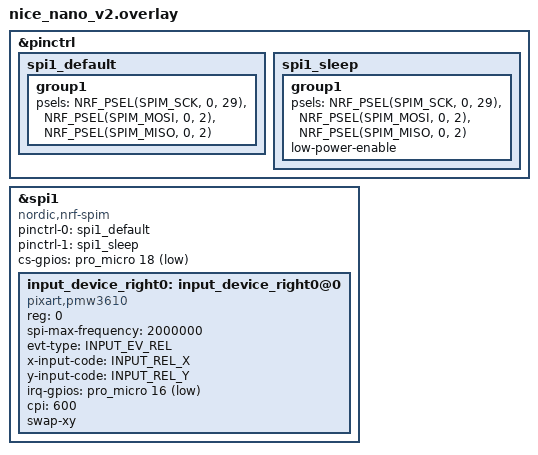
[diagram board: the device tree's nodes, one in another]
/**
 * Generated by Shield Wizard for ZMK
 * Applies to part "right" with controller "nice_nano_v2"
 */

// pin control for spi1
// - SCK on D20
// - MOSI on D19
// - MISO on D19
&pinctrl {
    /* configuration for spi1 device, default state */
    spi1_default: spi1_default {
        group1 {
            psels = <NRF_PSEL(SPIM_SCK, 0, 29)>,
                    <NRF_PSEL(SPIM_MOSI, 0, 2)>,
                    <NRF_PSEL(SPIM_MISO, 0, 2)>;
        };
    };
    /* configuration for spi1 device, sleep state */
    spi1_sleep: spi1_sleep {
        group1 {
            psels = <NRF_PSEL(SPIM_SCK, 0, 29)>,
                    <NRF_PSEL(SPIM_MOSI, 0, 2)>,
                    <NRF_PSEL(SPIM_MISO, 0, 2)>;
            low-power-enable;
        };
    };
};
&spi1 {
    compatible = "nordic,nrf-spim";
    status = "okay";
    pinctrl-0 = <&spi1_default>;
    pinctrl-1 = <&spi1_sleep>;
    pinctrl-names = "default", "sleep";
};

// devices on spi1

// CS pins for devices on spi1
&spi1 {
    cs-gpios = <&pro_micro 18 GPIO_ACTIVE_LOW>;
};

#include <zephyr/dt-bindings/input/input-event-codes.h>

&spi1 {
    input_device_right0: input_device_right0@0 {
        status = "okay";
        compatible = "pixart,pmw3610";
        reg = <0>;
        spi-max-frequency = <2000000>;
        evt-type = <INPUT_EV_REL>;
        x-input-code = <INPUT_REL_X>;
        y-input-code = <INPUT_REL_Y>;
        irq-gpios = <&pro_micro 16 (GPIO_ACTIVE_LOW | GPIO_PULL_UP)>;
        cpi = <600>;
        swap-xy;
    };
};
